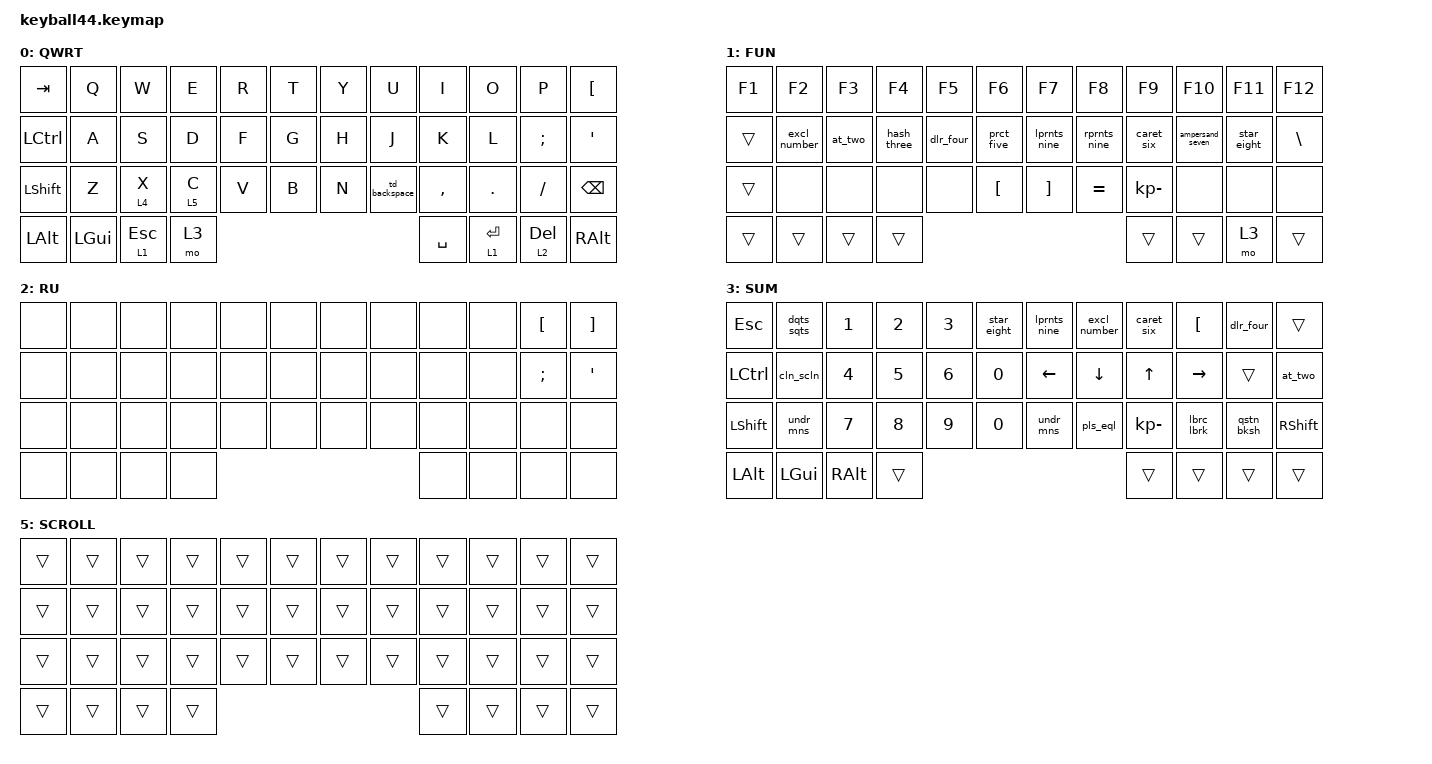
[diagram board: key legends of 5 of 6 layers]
#define DEFAULT 0
#define FUN 1
#define SYM 2
#define RU 3
#define MOUSE 4
#define SCROLL 5

#include <behaviors/mouse_keys.dtsi>
#include <behaviors.dtsi>
#include <dt-bindings/zmk/bt.h>
#include <dt-bindings/zmk/keys.h>
#include <dt-bindings/zmk/mouse.h>

&lt {
    tapping-term-ms = <240>;
    flavor = "balanced";
    quick-tap-ms = <150>;
};

&mt {
    tapping-term-ms = <200>;
    flavor = "tap-preferred";
    quick-tap-ms = <150>;
};

&caps_word { continue-list = <UNDERSCORE MINUS>; };

/ {
    // custom shift using mod-morph 

    behaviors {
        cmqus: comma_question {
            compatible = "zmk,behavior-mod-morph";
            #binding-cells = <0>;
            bindings = <&kp COMMA>, <&kp QUESTION>;

            mods = <(MOD_LSFT|MOD_RSFT)>;
        };

        dtsmi: dot_semi {
            compatible = "zmk,behavior-mod-morph";
            #binding-cells = <0>;
            bindings = <&kp DOT>, <&kp SEMI>;

            mods = <(MOD_LSFT|MOD_RSFT)>;
        };

         excl_number: excl_number {
            compatible = "zmk,behavior-mod-morph";
            #binding-cells = <0>;
            bindings = <&kp EXCL>, <&kp N1>;

            mods = <(MOD_LSFT|MOD_RSFT)>;
        };

        at_two: at_two {
            compatible = "zmk,behavior-mod-morph";
            #binding-cells = <0>;
            bindings = <&kp AT>, <&kp N2>;

            mods = <(MOD_LSFT|MOD_RSFT)>;
        };
        hash_three: hash_three {
            compatible = "zmk,behavior-mod-morph";
            #binding-cells = <0>;
            bindings = <&kp HASH>, <&kp N3>;

            mods = <(MOD_LSFT|MOD_RSFT)>;
        };
        dlr_four: dlr_four {
            compatible = "zmk,behavior-mod-morph";
            #binding-cells = <0>;
            bindings = <&kp DOLLAR>, <&kp N4>;

            mods = <(MOD_LSFT|MOD_RSFT)>;
        };
        prct_five: prct_five {
            compatible = "zmk,behavior-mod-morph";
            #binding-cells = <0>;
            bindings = <&kp PERCENT>, <&kp N5>;

            mods = <(MOD_LSFT|MOD_RSFT)>;
        };
        lprnts_nine: lprnts_nine {
            compatible = "zmk,behavior-mod-morph";
            #binding-cells = <0>;
            bindings = <&kp LEFT_PARENTHESIS>, <&kp N9>;

            mods = <(MOD_LSFT|MOD_RSFT)>;
        };
        rprnts_nine: rprnts_nine {
            compatible = "zmk,behavior-mod-morph";
            #binding-cells = <0>;
            bindings = <&kp RIGHT_PARENTHESIS>, <&kp N0>;

            mods = <(MOD_LSFT|MOD_RSFT)>;
        };
        caret_six: caret_six {
            compatible = "zmk,behavior-mod-morph";
            #binding-cells = <0>;
            bindings = <&kp CARET>, <&kp N6>;

            mods = <(MOD_LSFT|MOD_RSFT)>;
        };
        ampersand_seven: ampersand_seven {
            compatible = "zmk,behavior-mod-morph";
            #binding-cells = <0>;
            bindings = <&kp AMPERSAND>, <&kp N7>;

            mods = <(MOD_LSFT|MOD_RSFT)>;
        };
        star_eight: star_eight {
            compatible = "zmk,behavior-mod-morph";
            #binding-cells = <0>;
            bindings = <&kp STAR>, <&kp N8>;

            mods = <(MOD_LSFT|MOD_RSFT)>;
        };
        //
        dqts_sqts: dqts_sqts {
            compatible = "zmk,behavior-mod-morph";
            #binding-cells = <0>;
            bindings = <&kp DOUBLE_QUOTES>, <&kp SINGLE_QUOTE>;

            mods = <(MOD_LSFT|MOD_RSFT)>;
        };
        cln_scln: cln_scln {
            compatible = "zmk,behavior-mod-morph";
            #binding-cells = <0>;
            bindings = <&kp COLON>, <&kp SEMICOLON>;

            mods = <(MOD_LSFT|MOD_RSFT)>;
        };
        undr_mns: undr_mns {
            compatible = "zmk,behavior-mod-morph";
            #binding-cells = <0>;
            bindings = <&kp UNDER>, <&kp KP_MINUS>;

            mods = <(MOD_LSFT|MOD_RSFT)>;
        };
        pls_eql: pls_eql {
            compatible = "zmk,behavior-mod-morph";
            #binding-cells = <0>;
            bindings = <&kp PLUS>, <&kp KP_EQUAL>;

            mods = <(MOD_LSFT|MOD_RSFT)>;
        };
        lbrc_lbrk: lbrc_lbrk {
            compatible = "zmk,behavior-mod-morph";
            #binding-cells = <0>;
            bindings = <&kp LBRC>, <&kp LEFT_BRACKET>;

            mods = <(MOD_LSFT|MOD_RSFT)>;
        };
        qstn_bksh: qstn_bksh {
            compatible = "zmk,behavior-mod-morph";
            #binding-cells = <0>;
            bindings = <&kp QUESTION>, <&kp BACKSLASH>;

            mods = <(MOD_LSFT|MOD_RSFT)>;
        };
        td_backspace: td_backspace {
            compatible = "zmk,behavior-tap-dance";
            #binding-cells = <0>;
            tapping-term-ms = <200>; // Время между нажатиями для распознавания двойного тапа
            bindings = <&kp M>, <&kp RIGHT_BRACKET>; // Первое нажатие — Backspace, второе — Delete
        };
    };

    keymap {
        compatible = "zmk,keymap";

        default_layer {
            label = "QWRT";
            bindings = <
&kp TAB    &kp Q     &kp  W     &kp E    &kp R  &kp T       &kp Y  &kp U  &kp I      &kp O    &kp P      &kp LEFT_BRACKET
&kp LCTRL  &kp A     &kp S      &kp D    &kp F  &kp G       &kp H  &kp J  &kp K      &kp L    &kp SEMI   &kp SINGLE_QUOTE
&kp LSHFT  &kp Z     &lt 4 X    &lt 5 C  &kp V  &kp B       &kp N  &td_backspace  &kp COMMA  &kp DOT  &kp SLASH  &kp BACKSPACE
&kp LALT   &kp LGUI  &lt 1 ESC  &mo 3    &kp SPACE          &lt 1 RET  &lt 2 DEL                         &kp RALT
            >;
        };

        function_layer {
            label = "FUN";
            bindings = <
&kp F1  &kp F2          &kp F3   &kp F4       &kp F5       &kp F6             &kp F7        &kp F8        &kp F9        &kp F10           &kp F11      &kp F12
&trans  &excl_number    &at_two  &hash_three  &dlr_four    &prct_five         &lprnts_nine  &rprnts_nine  &caret_six    &ampersand_seven  &star_eight  &kp BACKSLASH
&trans  &none           &none    &none        &none        &kp LBKT           &kp RBKT      &kp EQUAL     &kp KP_MINUS  &none             &none        &none
&trans  &trans  &trans  &trans   &trans                                       &trans        &mo 3                                                      &trans
            >;
        };
 
        ru_layer {
            label = "RU";
            bindings = <
&none  &none  &none  &none  &none  &none              &none  &none  &none  &none  &kp LEFT_BRACKET  &kp RIGHT_BRACKET
&none  &none  &none  &none  &none  &none              &none  &none  &none  &none  &kp SEMI          &kp SINGLE_QUOTE
&none  &none  &none  &none  &none  &none              &none  &none  &none  &none  &none             &none
&none  &none  &none  &none  &none              &none  &none                                         &none
            >;
        };

        symbol_layer {
            label = "SUM";
            bindings = <
&kp ESC    &dqts_sqts  &kp NUMBER_1  &kp NUMBER_2  &kp NUMBER_3  &star_eight            &lprnts_nine    &excl_number    &caret_six    &kp LEFT_BRACKET  &dlr_four   &trans
&kp LCTRL  &cln_scln   &kp NUMBER_4  &kp NUMBER_5  &kp NUMBER_6  &kp NUMBER_0           &kp LEFT_ARROW  &kp DOWN_ARROW  &kp UP_ARROW  &kp RIGHT_ARROW   &trans      &at_two
&kp LSHFT  &undr_mns   &kp NUMBER_7  &kp NUMBER_8  &kp NUMBER_9  &kp NUMBER_0           &undr_mns       &pls_eql        &kp KP_MINUS  &lbrc_lbrk        &qstn_bksh  &kp RSHFT
&kp LALT   &kp LGUI    &kp RALT      &trans        &trans        &trans                 &trans                                                                      &trans
            >;
        };

        mouse_layer {
            label = "MOUSE";
            bindings = <
&none   &kp N1          &kp N2          &kp N3        &kp N4     &kp N5              &kp N6         &kp N7     &kp N8  &kp N9     &kp N0     &none
&none   &kp LEFT_ARROW  &kp DOWN_ARROW  &kp UP_ARROW  &kp RIGHT  &none               &kp PAGE_UP    &mkp LCLK  &none   &mkp RCLK  &mkp MCLK  &none
&none   &none           &none           &none         &none      &none               &kp PAGE_DOWN  &none      &none   &none      &none      &none
&trans  &trans          &trans          &trans        &trans                 &trans  &trans  
            >;
        };

        scroll_layer {
            label = "SCROLL";
            bindings = <
&trans  &trans  &trans  &trans  &trans  &trans              &trans  &trans  &trans  &trans  &trans  &trans
&trans  &trans  &trans  &trans  &trans  &trans              &trans  &trans  &trans  &trans  &trans  &trans
&trans  &trans  &trans  &trans  &trans  &trans              &trans  &trans  &trans  &trans  &trans  &trans
&trans  &trans  &trans  &trans  &trans                      &trans  &trans                          &trans
            >;
        };
    };
};
